# C2000_USB_Type0_Registers register map
Vendor: Texas Instruments
Peripheral module from a debugger description file (folder C2000).
Address unit: 16 bits
Registers are 16-bit, access not given, no defined reset value unless marked. A register's access mark holds for its fields unless they carry their own. Offsets are as the file gives them; lines under a group give offsets from that group; [hi:lo] are bit positions; {n}, {i} and the like mark numbered series; 'fields as' and 'values as' point back to an identical list; <NAME> marks a mode.

## USB0 — USB Registers
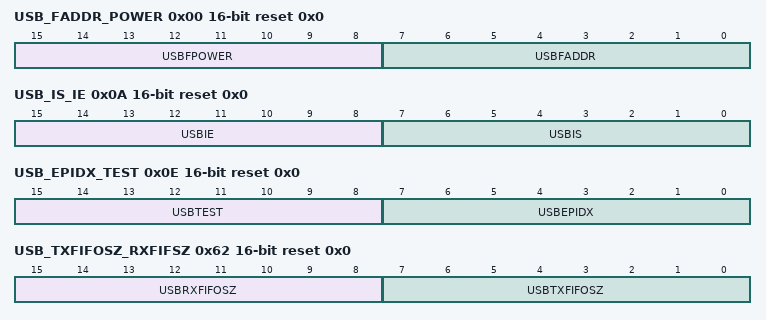
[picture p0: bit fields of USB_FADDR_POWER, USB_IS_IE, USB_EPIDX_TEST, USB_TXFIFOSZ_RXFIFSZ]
0x00 USB_FADDR_POWER rw reset 0x0 — USB FADDR and POWER
  [15:8] USBFPOWER — USB Power
  [7:0] USBFADDR — USB Device Functional Address
0x02 USBTXIS — USB Transmit Interrupt Status
0x04 USBRXIS — USB Receive Interrupt Status
0x06 USBTXIE — USB Transmit Interrupt Enable
0x08 USBRXIE — USB Receive Interrupt Enable
0x0A USB_IS_IE rw reset 0x0 — USB IS and IE
  [15:8] USBIE — USB Interrupt Enable
  [7:0] USBIS — USB General Interrupt Status
0x0C USBFRAME — USB Frame Value
0x0E USB_EPIDX_TEST rw reset 0x0 — USB EPIDX and TEST
  [15:8] USBTEST — USB Test Mode
  [7:0] USBEPIDX — USB Endpoint Index
{0x20+4i} USBFIFO{i} 32-bit (i=0..3) — USB FIFO Endpoint {i}
0x60 USBDEVCTL rw reset 0x0
  [7:0] USBDEVCTL — USB Endpoint Index
0x62 USB_TXFIFOSZ_RXFIFSZ rw reset 0x0 — USB TXFIFOSZ and RXFIFSZ
  [15:8] USBRXFIFOSZ — USB Receive Dynamic FIFO Sizing
  [7:0] USBTXFIFOSZ — USB Transmit Dynamic FIFO Sizing
0x64 USBTXFIFOADD — USB Transmit FIFO Start Address
0x66 USBRXFIFOADD — USB Receive FIFO Start Address
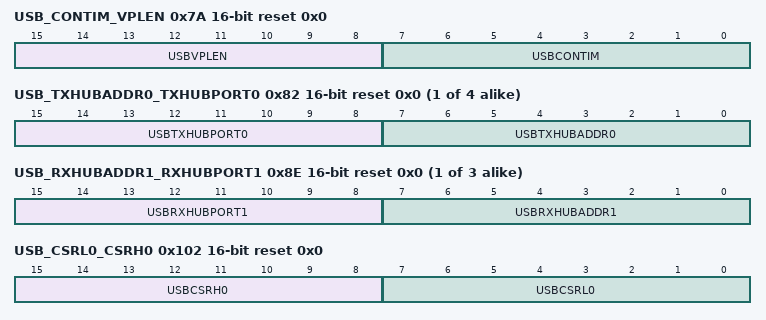
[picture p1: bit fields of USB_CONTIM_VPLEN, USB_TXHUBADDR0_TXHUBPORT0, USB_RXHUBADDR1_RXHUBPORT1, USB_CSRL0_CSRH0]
0x7A USB_CONTIM_VPLEN rw reset 0x0 — USB CONTIM and VPLEN
  [15:8] USBVPLEN — USB OTG VBUS Pulse Timing
  [7:0] USBCONTIM — USB Connect Timin
0x7C USBFSEOF rw reset 0x0 — USBFSEOFF
  [15:8] USBFSEOF — USB Full-Speed Last Transaction to End of Frame Timing
0x7E USBLSEOF rw reset 0x0
  [7:0] USBLSEOF — USB Low-Speed Last Transaction to End of Frame Timing
{0x80+8i} USBTXFUNCADDR{i} rw reset 0x0 (i=0..3)
  [7:0] USBTXFUNCADDR{i} — USB Transmit Functional Address Endpoint {i}
{0x82+8i} USB_TXHUBADDR{i}_TXHUBPORT{i} rw reset 0x0 (i=0..3) — USB TXHUBADDR{i} and TXHUBPORT{i}
  [15:8] USBTXHUBPORT{i} — USB Transmit Hub Port Endpoint {i}
  [7:0] USBTXHUBADDR{i} — USB Transmit Hub Address Endpoint {i}
{0x84+8i} USBRXFUNCADDR{i} rw reset 0x0 (i=1..3)
  [7:0] USBTXFUNCADDR{i} — USB Receive Functional Address Endpoint {i}
{0x86+8i} USB_RXHUBADDR{i}_RXHUBPORT{i} rw reset 0x0 (i=1..3) — USB RXHUBADDR{i} and RXHUBPORT{i}
  [15:8] USBRXHUBPORT{i} — USB Receive Hub Port Endpoint {i}
  [7:0] USBRXHUBADDR{i} — USB Receive Hub Address Endpoint {i}
0x102 USB_CSRL0_CSRH0 rw reset 0x0 — USB CSRL0 and CSRH0
  [15:8] USBCSRH0 — USB Control and Status Endpoint 0 High
  [7:0] USBCSRL0 — USB Control and Status Endpoint 0 Low
0x106 USBCOUNT0 rw reset 0x0
  [7:0] USBCOUNT0 — USB Receive Byte Count Endpoint 0
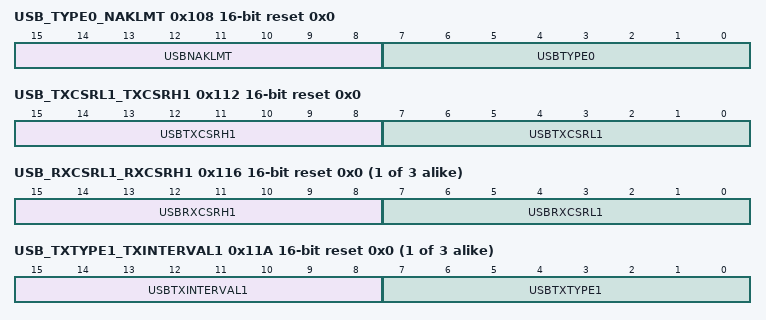
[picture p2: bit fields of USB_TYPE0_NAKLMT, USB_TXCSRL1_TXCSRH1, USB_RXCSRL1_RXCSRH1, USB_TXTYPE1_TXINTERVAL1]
0x108 USB_TYPE0_NAKLMT rw reset 0x0 — USB TYPE0 and NAKLMT
  [15:8] USBNAKLMT — USB NAK Limit
  [7:0] USBTYPE0 — USB Type Endpoint 0
{0x100+0x10*i} USBTXMAXP{i} (i=1..3) — USB Maximum Transmit Data Endpoint {i}
0x112 USB_TXCSRL1_TXCSRH1 rw reset 0x0 — USB TXCSRL1 and TXCSRH1
  [15:8] USBTXCSRH1 — USB Transmit Control and Status Endpoint 1 High
  [7:0] USBTXCSRL1 — USB Transmit Control and Status Endpoint 1 Low
{0x104+0x10*i} USBRXMAXP{i} (i=1..3) — USB Maximum Receive Data Endpoint {i}
{0x106+0x10*i} USB_RXCSRL{i}_RXCSRH{i} rw reset 0x0 (i=1..3) — USB RXCSRL{i} and RXCSRH{i}
  [15:8] USBRXCSRH{i} — USB Receive Control and Status Endpoint {i} High
  [7:0] USBRXCSRL{i} — USB Receive Control and Status Endpoint {i} Low
{0x108+0x10*i} USBRXCOUNT{i} (i=1..3) — USB Receive Byte Count Endpoint {i}
{0x10A+0x10*i} USB_TXTYPE{i}_TXINTERVAL{i} rw reset 0x0 (i=1..3) — USB TXTYPE{i} and TXINTERVAL{i}
  [15:8] USBTXINTERVAL{i} — USB Host Transmit Interval Endpoint {i}
  [7:0] USBTXTYPE{i} — USB Host Transmit Configure Type Endpoint {i}
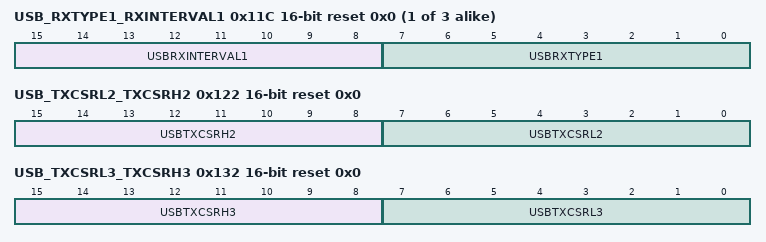
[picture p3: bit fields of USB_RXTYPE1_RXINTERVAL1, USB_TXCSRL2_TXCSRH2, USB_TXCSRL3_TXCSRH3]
{0x10C+0x10*i} USB_RXTYPE{i}_RXINTERVAL{i} rw reset 0x0 (i=1..3) — USB RXTYPE{i} and RXINTERVAL{i}
  [15:8] USBRXINTERVAL{i} — USB Host Receive Interval Endpoint {i}
  [7:0] USBRXTYPE{i} — USB Host Receive Configure Type Endpoint {i}
0x122 USB_TXCSRL2_TXCSRH2 rw reset 0x0 — USB TXCSRL2 and TXCSRH2
  [15:8] USBTXCSRH2 — USB Transmit Control and Status Endpoint 2 High
  [7:0] USBTXCSRL2 — USB Transmit Control and Status Endpoint 2 Low
0x132 USB_TXCSRL3_TXCSRH3 rw reset 0x0 — USB TXCSRL32 and TXCSRH3
  [15:8] USBTXCSRH3 — USB Transmit Control and Status Endpoint 3 High
  [7:0] USBTXCSRL3 — USB Transmit Control and Status Endpoint 3 Low
{0x300+4i} USBRQPKTCOUNT{i} (i=1..3) — USB Request Packet Count in Block Transfer Endpoint {i}
0x340 USBRXDPKTBUFDIS — USB Receive Double Packet Buffer Disable
0x342 USBTXDPKTBUFDIS — USB Transmit Double Packet Buffer Disable
0x400 USBEPC 32-bit — USB External Power Control
0x404 USBEPCRIS 32-bit — USB External Power Control Raw Interrupt Status
0x408 USBEPCIM 32-bit — USB External Power Control Interrupt Mask
0x40C USBEPCISC 32-bit — USB External Power Control Interrupt Status and Clear
0x410 USBDRRIS 32-bit — USB Device RESUME Raw Interrupt Status
0x414 USBDRIM 32-bit — USB Device RESUME Interrupt Mask
0x418 USBDRISC 32-bit — USB Device RESUME Interrupt Status and Clear
0x41C USBGPCS 32-bit — USB General-Purpose Control and Status
0x430 USBVDC 32-bit — USB VBUS Droop Control
0x434 USBVDCRIS 32-bit — USB VBUS Droop Control Raw Interrupt Status
0x438 USBVDCIM 32-bit — USB VBUS Droop Control Interrupt Mask
0x43C USBVDCISC 32-bit — USB VBUS Droop Control Interrupt Status and Clear
0x444 USBIDVRIS 32-bit — USB ID Valid Detect Raw Interrupt Status
0x448 USBIDVIM 32-bit — USB ID Valid Detect Interrupt Mask
0x44C USBIDVISC 32-bit — USB ID Valid Detect Interrupt Status and Clear
0x450 USBDMASEL 32-bit — USB DMA Select
